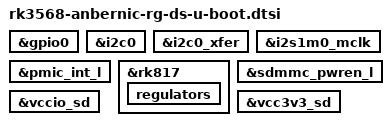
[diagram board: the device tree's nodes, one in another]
// SPDX-License-Identifier: GPL-2.0+

#include "rk3568-u-boot.dtsi"

&gpio0 {
	bootph-pre-ram;
};

&i2c0 {
	bootph-pre-ram;
};

&i2c0_xfer {
	bootph-pre-ram;
};

&i2s1m0_mclk {
	bootph-pre-ram;
};

&pmic_int_l {
	bootph-pre-ram;
};

&rk817 {
	regulators {
		bootph-pre-ram;
	};
};

&sdmmc_pwren_l {
	bootph-pre-ram;
};

&vcc3v3_sd {
	bootph-pre-ram;
};

&vccio_sd {
	bootph-pre-ram;
};
